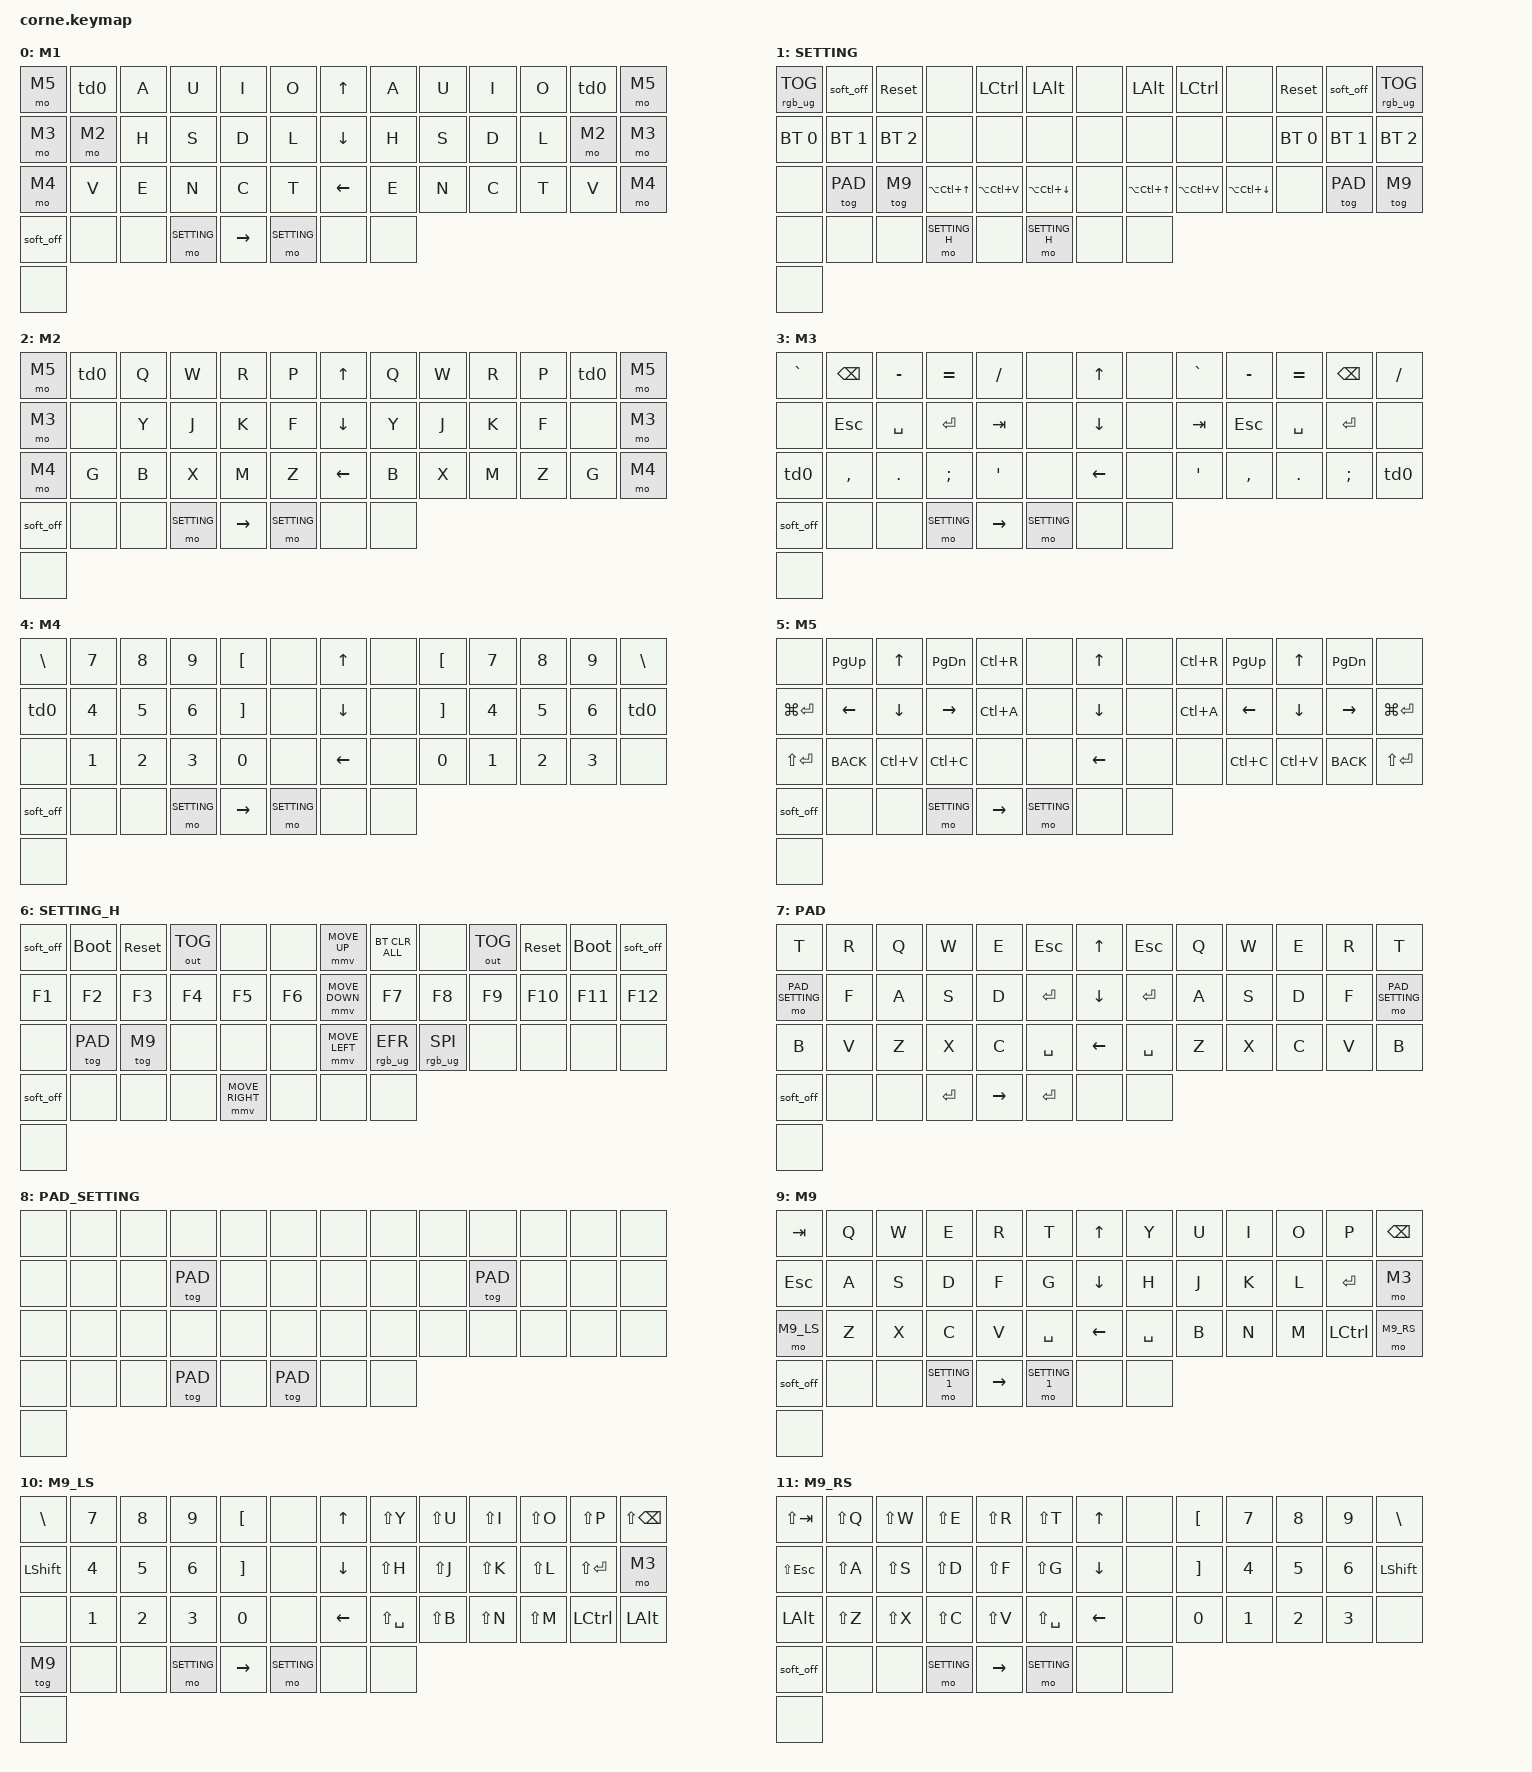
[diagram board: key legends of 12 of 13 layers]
#include <behaviors/mouse_keys.dtsi>
#include <behaviors.dtsi>
#include <dt-bindings/zmk/bt.h>
#include <dt-bindings/zmk/keys.h>
#include <dt-bindings/zmk/mouse.h>
#include <dt-bindings/zmk/outputs.h>
#include <dt-bindings/zmk/rgb.h>

#define ZMK_MOUSE_DEFAULT_MOVE_VAL 1200  // 600
#define ZMK_MOUSE_DEFAULT_SCRL_VAL 20    // 10
#define M1           0
#define SETTING      1
#define M2           2
#define M3           3
#define M4           4
#define M5           5
#define SETTING_H    6
#define PAD          7
#define PAD_SETTING  8
#define M9           9
#define M9_LS        10
#define M9_RS        11
#define SETTING_1    12

/ {
    behaviors {
        td0: td0 {
            compatible = "zmk,behavior-tap-dance";
            #binding-cells = <0>;
            bindings = <&kp LEFT_SHIFT>, <&kp CAPS>;
        };

        mmv {
            acceleration-exponent = <1>;      // 1
            time-to-max-speed-ms = <900>;    // 40
            delay-ms = <0>;                   // 0
        };

        msc {
            acceleration-exponent = <1>;      // 0
            time-to-max-speed-ms = <400>;      // 500
            delay-ms = <0>;                   // 10
        };
    };

    rgb_encoder: rgb_encoder {
        compatible = "zmk,behavior-sensor-rotate";
        #sensor-binding-cells = <0>;
        bindings = <&rgb_ug RGB_BRI>, <&rgb_ug RGB_BRD>;
    };

    scroll_encoder: scroll_encoder {
        compatible = "zmk,behavior-sensor-rotate";
        #sensor-binding-cells = <0>;
        bindings = <&msc SCRL_DOWN>, <&msc SCRL_UP>;

        tap-ms = <30>;
    };


	rot_kp: sensor_rotate_kp {
		compatible = "zmk,behavior-sensor-rotate-var";
		#sensor-binding-cells = <2>;
		bindings = <&kp>, <&kp>;
		tap-ms = <10>;
	};

    keymap {
        compatible = "zmk,keymap";

        m1 {
            display-name = "M1";
		    bindings = <
&mo M5  &td0   &kp A  &kp U  &kp I  &kp O    &kp UP_ARROW       &kp A  &kp U  &kp I  &kp O  &td0   &mo M5
&mo M3  &mo M2  &kp H  &kp S  &kp D  &kp L    &kp DOWN_ARROW     &kp H  &kp S  &kp D  &kp L  &mo M2  &mo M3
&mo M4  &kp V  &kp E  &kp N  &kp C  &kp T    &kp LEFT_ARROW     &kp E  &kp N  &kp C  &kp T  &kp V  &mo M4
       &soft_off    &none  &none  &mo SETTING     &kp RIGHT_ARROW    &mo SETTING  &none  &none
                                            &none
            >;
			sensor-bindings = <&rot_kp PAGE_DOWN PAGE_UP>;
        };

        setting {
            display-name = "SETTING";
            bindings = <
/////////////////////////////////////////////////////////////////////////////////////////////////////////////////
&rgb_ug RGB_TOG  &soft_off     &sys_reset    &none                 &kp LCTRL      &kp LALT                  &none    &kp LALT              &kp LCTRL      &none 	           &sys_reset    &soft_off     &rgb_ug RGB_TOG
/////////////////////////////////////////////////////////////////////////////////////////////////////////////////
&bt BT_SEL 0     &bt BT_SEL 1  &bt BT_SEL 2  &none                 &none          &none                     &none    &none                 &none          &none                 &bt BT_SEL 0  &bt BT_SEL 1  &bt BT_SEL 2
/////////////////////////////////////////////////////////////////////////////////////////////////////////////////
&none            &tog PAD      &tog M9       &kp LA(LC(UP_ARROW))  &kp LA(LC(V))  &kp LA(LC(DOWN_ARROW))    &none    &kp LA(LC(UP_ARROW))  &kp LA(LC(V))  &kp LA(LC(DOWN_ARROW))  &none         &tog PAD      &tog M9
/////////////////////////////////////////////////////////////////////////////////////////////////////////////////
&none  &none &none  &mo SETTING_H 	   								    &none    &mo SETTING_H &none  &none
&none
            >;
            sensor-bindings = <&inc_dec_kp K_VOLUME_UP K_VOLUME_DOWN>;
        };


        m2 {
            display-name = "M2";
            bindings = <
&mo M5  &td0   &kp Q  &kp W  &kp R  &kp P    &kp UP_ARROW     &kp Q  &kp W  &kp R  &kp P  &td0   &mo M5
&mo M3  &none  &kp Y  &kp J  &kp K  &kp F    &kp DOWN_ARROW   &kp Y  &kp J  &kp K  &kp F  &none  &mo M3
&mo M4  &kp G  &kp B  &kp X  &kp M  &kp Z    &kp LEFT_ARROW   &kp B  &kp X  &kp M  &kp Z  &kp G  &mo M4
       &soft_off    &none  &none  &mo SETTING     &kp RIGHT_ARROW  &mo SETTING  &none  &none
	   &none
            >;
            sensor-bindings = <&scroll_encoder>;
        };

        m3 {
            display-name = "M3";
            bindings = <
&kp GRAVE  &kp BSPC   &kp MINUS   &kp EQUAL  &kp SLASH       &none    &kp UP_ARROW       &none  &kp GRAVE       &kp MINUS  &kp EQUAL   &kp BSPC   &kp SLASH
&none      &kp ESC    &kp SPACE   &kp ENTER  &kp TAB  		 &none    &kp DOWN_ARROW     &none  &kp TAB         &kp ESC    &kp SPACE   &kp ENTER  &none
&td0       &kp COMMA  &kp PERIOD  &kp SEMI   &kp APOSTROPHE  &none    &kp LEFT_ARROW     &none  &kp APOSTROPHE  &kp COMMA  &kp PERIOD  &kp SEMI   &td0
           &soft_off    &none  &none  &mo SETTING     					  &kp RIGHT_ARROW    &mo SETTING  &none  &none
           &none
            >;
            sensor-bindings = <&scroll_encoder>;
        };

        m4 {
            display-name = "M4";
            bindings = <
&kp BACKSLASH  &kp N7  &kp N8  &kp N9  &kp LEFT_BRACKET   &none    &kp UP_ARROW       &none  &kp LEFT_BRACKET   &kp N7  &kp N8  &kp N9  &kp BACKSLASH
&td0           &kp N4  &kp N5  &kp N6  &kp RIGHT_BRACKET  &none    &kp DOWN_ARROW     &none  &kp RIGHT_BRACKET  &kp N4  &kp N5  &kp N6  &td0
&none          &kp N1  &kp N2  &kp N3  &kp N0             &none    &kp LEFT_ARROW     &none  &kp N0             &kp N1  &kp N2  &kp N3  &none
               &soft_off    &none  &none  &mo SETTING                    &kp RIGHT_ARROW    &mo SETTING  &none  &none
               &none
            >;
            sensor-bindings = <&scroll_encoder>;
        };

        m5 {
            display-name = "M5";
            bindings = <
&none          &kp PAGE_UP     &kp UP_ARROW    &kp PAGE_DOWN    &kp LC(R)  &none    &kp UP_ARROW       &none  &kp LC(R)  &kp PAGE_UP     &kp UP_ARROW    &kp PAGE_DOWN    &none

&kp LG(ENTER)  &kp LEFT_ARROW  &kp DOWN_ARROW  &kp RIGHT_ARROW  &kp LC(A)  &none    &kp DOWN_ARROW     &none  &kp LC(A)  &kp LEFT_ARROW  &kp DOWN_ARROW  &kp RIGHT_ARROW  &kp LG(ENTER)

&kp LS(ENTER)  &kp K_BACK      &kp LC(V)       &kp LC(C)  		&none      &none    &kp LEFT_ARROW     &none  &none      &kp LC(C)       &kp LC(V)       &kp K_BACK       &kp LS(ENTER)

               &soft_off    &none  &none  &mo SETTING                                     &kp RIGHT_ARROW    &mo SETTING  &none  &none
               &none
            >;
            sensor-bindings = <&scroll_encoder>;
        };

        setting_h {
            display-name = "SETTING_H";
            bindings = <
&soft_off  &bootloader  &sys_reset  &out OUT_TOG   &none   &none     &mmv MOVE_UP      &bt BT_CLR_ALL   &none            &out OUT_TOG   &sys_reset  &bootloader  &soft_off
&kp F1     &kp F2       &kp F3      &kp F4  &kp F5  &kp F6    &mmv MOVE_DOWN    &kp F7           &kp F8           &kp F9  &kp F10     &kp F11      &kp F12
&none     &tog PAD        &tog M9       &none   &none   &none     &mmv MOVE_LEFT    &rgb_ug RGB_EFR  &rgb_ug RGB_SPI  &none   &none       &none        &none
           &soft_off   &none &none  &none                     &mmv MOVE_RIGHT &none &none  &none
                                                &none
            >;
            sensor-bindings = <&rgb_encoder>;
        };

        pad {
            display-name = "PAD";
		    bindings = <
/////////////////////////////////////////////////////////////////////////
&kp T            &kp R  &kp Q  &kp W  &kp E  &kp ESC      &kp UP_ARROW       &kp ESC    &kp Q  &kp W  &kp E  &kp R  &kp T
/////////////////////////////////////////////////////////////////////////
&mo PAD_SETTING  &kp F  &kp A  &kp S  &kp D  &kp ENTER    &kp DOWN_ARROW     &kp ENTER  &kp A  &kp S  &kp D  &kp F  &mo PAD_SETTING
/////////////////////////////////////////////////////////////////////////
&kp B            &kp V  &kp Z  &kp X  &kp C  &kp SPACE    &kp LEFT_ARROW     &kp SPACE  &kp Z  &kp X  &kp C  &kp V  &kp B
/////////////////////////////////////////////////////////////////////////
&soft_off  &none  &none  &kp ENTER                        &kp RIGHT_ARROW    &kp ENTER  &none  &none
&none
            >;
			sensor-bindings = <&rot_kp PAGE_DOWN PAGE_UP>;
        };

        pad_setting {
            display-name = "PAD_SETTING";
		    bindings = <
&none  &none  &none  &none     &none  &none    &none    &none  &none  &none     &none  &none  &none
&none  &none  &none  &tog PAD  &none  &none    &none    &none  &none  &tog PAD  &none  &none  &none
&none  &none  &none  &none     &none  &none    &none    &none  &none  &none     &none  &none  &none
&none  &none  &none  &tog PAD                  &none    &tog PAD  &none  &none
&none
            >;
			sensor-bindings = <&rot_kp PAGE_DOWN PAGE_UP>;
        };

        m9 {
            display-name = "M9";
		    bindings = <
&kp TAB  &kp Q  &kp W  &kp E  &kp R  &kp T        &kp UP_ARROW       &kp Y      &kp U  &kp I  &kp O  &kp P      &kp BSPC
&kp ESC  &kp A  &kp S  &kp D  &kp F  &kp G        &kp DOWN_ARROW     &kp H      &kp J  &kp K  &kp L  &kp ENTER  &mo M3
&mo M9_LS     &kp Z  &kp X  &kp C  &kp V  &kp SPACE    &kp LEFT_ARROW     &kp SPACE  &kp B  &kp N  &kp M  &kp LCTRL  &mo M9_RS       
         &soft_off    &none  &none  &mo SETTING_1         &kp RIGHT_ARROW    &mo SETTING_1  &none  &none
                                                  &none
            >;
			sensor-bindings = <&rot_kp PAGE_DOWN PAGE_UP>;
        };

        m9_ls {
            display-name = "M9_LS";
		    bindings = <
&kp BACKSLASH  &kp N7  &kp N8  &kp N9  &kp LEFT_BRACKET   &none        &kp UP_ARROW       &kp LS(Y)      &kp LS(U)  &kp LS(I)  &kp LS(O)  &kp LS(P)      &kp LS(BSPC)
&kp LSHIFT           &kp N4  &kp N5  &kp N6  &kp RIGHT_BRACKET  &none        &kp DOWN_ARROW     &kp LS(H)      &kp LS(J)  &kp LS(K)  &kp LS(L)  &kp LS(ENTER)  &mo M3
&none          &kp N1  &kp N2  &kp N3  &kp N0             &none        &kp LEFT_ARROW     &kp LS(SPACE)  &kp LS(B)  &kp LS(N)  &kp LS(M)  &kp LCTRL &kp LALT
         &tog M9    &none  &none  &mo SETTING   &kp RIGHT_ARROW    &mo SETTING  &none  &none
                                                  &none
            >;
			sensor-bindings = <&rot_kp PAGE_DOWN PAGE_UP>;
        };

        m9_rs {
            display-name = "M9_RS";
		    bindings = <
&kp LS(TAB)  &kp LS(Q)  &kp LS(W)  &kp LS(E)  &kp LS(R)  &kp LS(T)        &kp UP_ARROW       &none  &kp LEFT_BRACKET   &kp N7  &kp N8  &kp N9  &kp BACKSLASH
&kp LS(ESC)  &kp LS(A)  &kp LS(S)  &kp LS(D)  &kp LS(F)  &kp LS(G)        &kp DOWN_ARROW     &none  &kp RIGHT_BRACKET  &kp N4  &kp N5  &kp N6  &kp LSHIFT
&kp LALT     &kp LS(Z)  &kp LS(X)  &kp LS(C)  &kp LS(V)  &kp LS(SPACE)    &kp LEFT_ARROW     &none  &kp N0             &kp N1  &kp N2  &kp N3  &none
         &soft_off    &none  &none  &mo SETTING   &kp RIGHT_ARROW    &mo SETTING  &none  &none
                                                  &none
            >;
			sensor-bindings = <&rot_kp PAGE_DOWN PAGE_UP>;
        };

        setting_1 {
            display-name = "SETTING";
            bindings = <
&rgb_ug RGB_TOG  &soft_off     &sys_reset         &none                 &none                   &none            &mmv MOVE_UP      &none                 &none                   &none 	&sys_reset  &soft_off     &rgb_ug RGB_TOG

&bt BT_SEL 0     &bt BT_SEL 1  &bt BT_SEL 2  &none                 &none                   &kp LS(ENTER)    &mmv MOVE_DOWN    &none                 &none                   &kp LS(ENTER)    &bt BT_SEL 0     &bt BT_SEL 1  &bt BT_SEL 2

&none           &tog PAD         &tog M9         &kp LA(LC(UP_ARROW))  &kp LA(LC(DOWN_ARROW))  &kp LA(LC(V))    &mmv MOVE_LEFT    &kp LA(LC(UP_ARROW))  &kp LA(LC(DOWN_ARROW))  &kp LA(LC(V))   &none           &tog PAD         &tog M9

                 &soft_off   &none &none  &mo SETTING_H    &mmv MOVE_RIGHT &mo SETTING_H &none  &none
				 &sys_reset
            >;
            sensor-bindings = <&rgb_encoder>;
        };



    };
};
